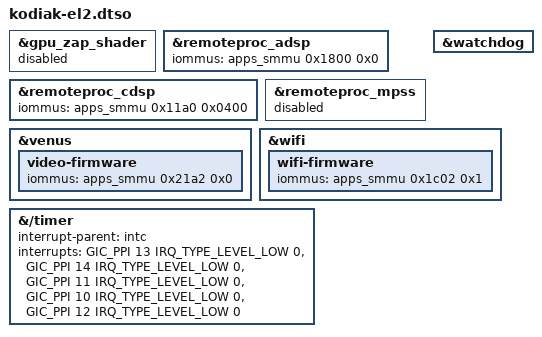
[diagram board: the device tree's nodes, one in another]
// SPDX-License-Identifier: BSD-3-Clause
/*
 * Copyright (c) Qualcomm Technologies, Inc. and/or its subsidiaries.
 *
 * Kodiak specific modifications required to boot in EL2.
 */

/dts-v1/;
/plugin/;

#include <dt-bindings/interrupt-controller/arm-gic.h>

&gpu_zap_shader {
	status = "disabled";
};

&remoteproc_adsp {
	iommus = <&apps_smmu 0x1800 0x0>;
};

&remoteproc_cdsp {
	iommus = <&apps_smmu 0x11a0 0x0400>;
};

&remoteproc_mpss {
	status = "disabled";
};

&venus {
	status = "okay";

	video-firmware {
		iommus = <&apps_smmu 0x21a2 0x0>;
	};
};

&watchdog {
	status = "okay";
};

&wifi {
	wifi-firmware {
		iommus = <&apps_smmu 0x1c02 0x1>;
	};
};

&{/timer} {
	interrupt-parent = <&intc>;
	interrupts = <GIC_PPI 13 IRQ_TYPE_LEVEL_LOW 0>,
		     <GIC_PPI 14 IRQ_TYPE_LEVEL_LOW 0>,
		     <GIC_PPI 11 IRQ_TYPE_LEVEL_LOW 0>,
		     <GIC_PPI 10 IRQ_TYPE_LEVEL_LOW 0>,
		     <GIC_PPI 12 IRQ_TYPE_LEVEL_LOW 0>;
};
